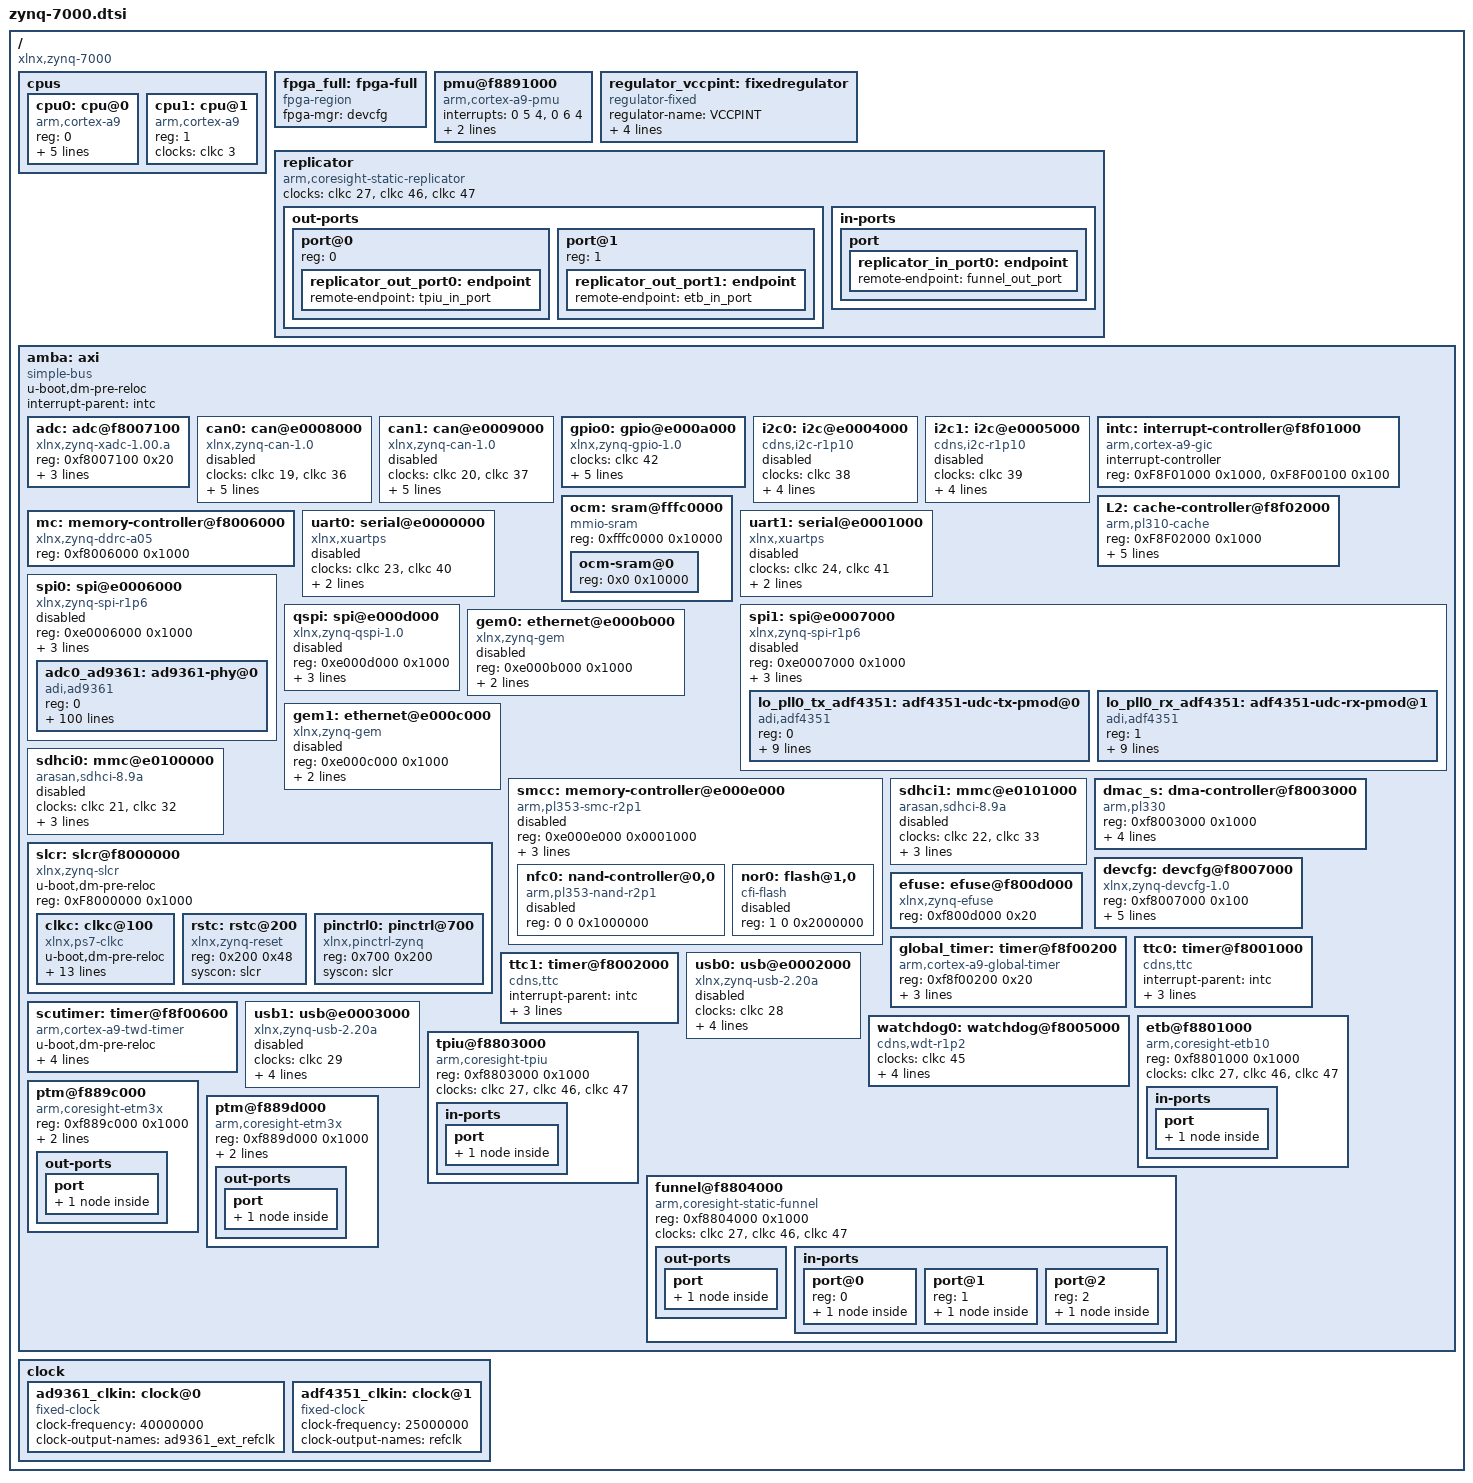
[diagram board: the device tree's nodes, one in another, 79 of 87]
// SPDX-License-Identifier: GPL-2.0+
/*
 * Xilinx Zynq 7000 DTSI
 * Describes the hardware common to all Zynq 7000-based boards.
 *
 *  Copyright (C) 2011 - 2015 Xilinx
 */

/ {
	#address-cells = <1>;
	#size-cells = <1>;
	compatible = "xlnx,zynq-7000";

	cpus {
		#address-cells = <1>;
		#size-cells = <0>;

		cpu0: cpu@0 {
			compatible = "arm,cortex-a9";
			device_type = "cpu";
			reg = <0>;
			clocks = <&clkc 3>;
			clock-latency = <1000>;
			cpu0-supply = <&regulator_vccpint>;
			operating-points = <
				/* kHz    uV */
				666667  1000000
				333334  1000000
			>;
		};

		cpu1: cpu@1 {
			compatible = "arm,cortex-a9";
			device_type = "cpu";
			reg = <1>;
			clocks = <&clkc 3>;
		};
	};

	fpga_full: fpga-full {
		compatible = "fpga-region";
		fpga-mgr = <&devcfg>;
		#address-cells = <1>;
		#size-cells = <1>;
		ranges;
	};

	pmu@f8891000 {
		compatible = "arm,cortex-a9-pmu";
		interrupts = <0 5 4>, <0 6 4>;
		interrupt-parent = <&intc>;
		reg = <0xf8891000 0x1000>,
		      <0xf8893000 0x1000>;
	};

	regulator_vccpint: fixedregulator {
		compatible = "regulator-fixed";
		regulator-name = "VCCPINT";
		regulator-min-microvolt = <1000000>;
		regulator-max-microvolt = <1000000>;
		regulator-boot-on;
		regulator-always-on;
	};

	replicator {
		compatible = "arm,coresight-static-replicator";
		clocks = <&clkc 27>, <&clkc 46>, <&clkc 47>;
		clock-names = "apb_pclk", "dbg_trc", "dbg_apb";

		out-ports {
			#address-cells = <1>;
			#size-cells = <0>;

			/* replicator output ports */
			port@0 {
				reg = <0>;
				replicator_out_port0: endpoint {
					remote-endpoint = <&tpiu_in_port>;
				};
			};
			port@1 {
				reg = <1>;
				replicator_out_port1: endpoint {
					remote-endpoint = <&etb_in_port>;
				};
			};
		};
		in-ports {
			/* replicator input port */
			port {
				replicator_in_port0: endpoint {
					remote-endpoint = <&funnel_out_port>;
				};
			};
		};
	};

	amba: axi {
		u-boot,dm-pre-reloc;
		compatible = "simple-bus";
		#address-cells = <1>;
		#size-cells = <1>;
		interrupt-parent = <&intc>;
		ranges;

		adc: adc@f8007100 {
			compatible = "xlnx,zynq-xadc-1.00.a";
			reg = <0xf8007100 0x20>;
			interrupts = <0 7 4>;
			interrupt-parent = <&intc>;
			clocks = <&clkc 12>;
		};

		can0: can@e0008000 {
			compatible = "xlnx,zynq-can-1.0";
			status = "disabled";
			clocks = <&clkc 19>, <&clkc 36>;
			clock-names = "can_clk", "pclk";
			reg = <0xe0008000 0x1000>;
			interrupts = <0 28 4>;
			interrupt-parent = <&intc>;
			tx-fifo-depth = <0x40>;
			rx-fifo-depth = <0x40>;
		};

		can1: can@e0009000 {
			compatible = "xlnx,zynq-can-1.0";
			status = "disabled";
			clocks = <&clkc 20>, <&clkc 37>;
			clock-names = "can_clk", "pclk";
			reg = <0xe0009000 0x1000>;
			interrupts = <0 51 4>;
			interrupt-parent = <&intc>;
			tx-fifo-depth = <0x40>;
			rx-fifo-depth = <0x40>;
		};

		gpio0: gpio@e000a000 {
			compatible = "xlnx,zynq-gpio-1.0";
			#gpio-cells = <2>;
			#address-cells = <0>;
			clocks = <&clkc 42>;
			gpio-controller;
			interrupt-controller;
			#interrupt-cells = <2>;
			interrupt-parent = <&intc>;
			interrupts = <0 20 4>;
			reg = <0xe000a000 0x1000>;
		};

		i2c0: i2c@e0004000 {
			compatible = "cdns,i2c-r1p10";
			status = "disabled";
			clocks = <&clkc 38>;
			interrupt-parent = <&intc>;
			interrupts = <0 25 4>;
			clock-frequency = <400000>;
			reg = <0xe0004000 0x1000>;
			#address-cells = <1>;
			#size-cells = <0>;
		};

		i2c1: i2c@e0005000 {
			compatible = "cdns,i2c-r1p10";
			status = "disabled";
			clocks = <&clkc 39>;
			interrupt-parent = <&intc>;
			interrupts = <0 48 4>;
			clock-frequency = <400000>;
			reg = <0xe0005000 0x1000>;
			#address-cells = <1>;
			#size-cells = <0>;
		};

		intc: interrupt-controller@f8f01000 {
			compatible = "arm,cortex-a9-gic";
			#interrupt-cells = <3>;
			#address-cells = <0>;
			interrupt-controller;
			reg = <0xF8F01000 0x1000>,
			      <0xF8F00100 0x100>;
		};

		L2: cache-controller@f8f02000 {
			compatible = "arm,pl310-cache";
			reg = <0xF8F02000 0x1000>;
			interrupts = <0 2 4>;
			arm,data-latency = <3 2 2>;
			arm,tag-latency = <2 2 2>;
			cache-unified;
			cache-level = <2>;
		};

		mc: memory-controller@f8006000 {
			compatible = "xlnx,zynq-ddrc-a05";
			reg = <0xf8006000 0x1000>;
		};

		ocm: sram@fffc0000 {
			compatible = "mmio-sram";
			reg = <0xfffc0000 0x10000>;
			#address-cells = <1>;
			#size-cells = <1>;
			ranges = <0 0xfffc0000 0x10000>;
			ocm-sram@0 {
				reg = <0x0 0x10000>;
			};
		};

		uart0: serial@e0000000 {
			compatible = "xlnx,xuartps", "cdns,uart-r1p8";
			status = "disabled";
			clocks = <&clkc 23>, <&clkc 40>;
			clock-names = "uart_clk", "pclk";
			reg = <0xE0000000 0x1000>;
			interrupts = <0 27 4>;
		};

		uart1: serial@e0001000 {
			compatible = "xlnx,xuartps", "cdns,uart-r1p8";
			status = "disabled";
			clocks = <&clkc 24>, <&clkc 41>;
			clock-names = "uart_clk", "pclk";
			reg = <0xE0001000 0x1000>;
			interrupts = <0 50 4>;
		};

		spi0: spi@e0006000 {
			compatible = "xlnx,zynq-spi-r1p6";
			reg = <0xe0006000 0x1000>;
			status = "disabled";
			interrupt-parent = <&intc>;
			interrupts = <0 26 4>;
			clocks = <&clkc 25>, <&clkc 34>;
			clock-names = "ref_clk", "pclk";
			#address-cells = <1>;
			#size-cells = <0>;
			adc0_ad9361: ad9361-phy@0 {
				compatible = "adi,ad9361";
				reg = <0>;

				/* SPI Setup */
				spi-cpha;
				spi-max-frequency = <10000000>;

				/* Clocks */
				clocks = <&ad9361_clkin 0>;
				clock-names = "ad9361_ext_refclk";
				clock-output-names = "rx_sampl_clk", "tx_sampl_clk";
				#clock-cells = <1>;

				//adi,debug-mode-enable;
				/* Digital Interface Control */

				/* adi,digital-interface-tune-skip-mode:
				* 0 = TUNE RX&TX
				* 1 = SKIP TX
				* 2 = SKIP ALL
				*/
				adi,digital-interface-tune-skip-mode = <0>;

				adi,pp-tx-swap-enable;
				adi,pp-rx-swap-enable;
				adi,rx-frame-pulse-mode-enable;
				adi,lvds-mode-enable;
				adi,lvds-bias-mV = <150>;
				adi,lvds-rx-onchip-termination-enable;
				adi,rx-data-delay = <4>;
				adi,tx-fb-clock-delay = <7>;

				//adi,fdd-rx-rate-2tx-enable;

				adi,dcxo-coarse-and-fine-tune = <8 5920>;
				//adi,xo-disable-use-ext-refclk-enable;

				/* Mode Setup */

				adi,2rx-2tx-mode-enable;
				//adi,split-gain-table-mode-enable;

				/* ENSM Mode */
				adi,frequency-division-duplex-mode-enable;
				//adi,ensm-enable-pin-pulse-mode-enable;
				//adi,ensm-enable-txnrx-control-enable;


				/* adi,rx-rf-port-input-select:
				* 0 = (RX1A_N &  RX1A_P) and (RX2A_N & RX2A_P) enabled; balanced
				* 1 = (RX1B_N &  RX1B_P) and (RX2B_N & RX2B_P) enabled; balanced
				* 2 = (RX1C_N &  RX1C_P) and (RX2C_N & RX2C_P) enabled; balanced
				*
				* 3 = RX1A_N and RX2A_N enabled; unbalanced
				* 4 = RX1A_P and RX2A_P enabled; unbalanced
				* 5 = RX1B_N and RX2B_N enabled; unbalanced
				* 6 = RX1B_P and RX2B_P enabled; unbalanced
				* 7 = RX1C_N and RX2C_N enabled; unbalanced
				* 8 = RX1C_P and RX2C_P enabled; unbalanced
				*/

				adi,rx-rf-port-input-select = <0>; /* (RX1A_N &  RX1A_P) and (RX2A_N & RX2A_P) enabled; balanced */

				/* adi,tx-rf-port-input-select:
				* 0	TX1A, TX2A
				* 1	TX1B, TX2B
				*/

				adi,tx-rf-port-input-select = <0>; /* TX1A, TX2A */
				//adi,update-tx-gain-in-alert-enable;
				adi,tx-attenuation-mdB = <10000>;
				adi,tx-lo-powerdown-managed-enable;

				adi,rf-rx-bandwidth-hz = <18000000>;
				adi,rf-tx-bandwidth-hz = <18000000>;
				adi,rx-synthesizer-frequency-hz = /bits/ 64 <2400000000>;
				adi,tx-synthesizer-frequency-hz = /bits/ 64 <2450000000>;

				/*				BBPLL     ADC        R2CLK     R1CLK    CLKRF    RSAMPL  */
				adi,rx-path-clock-frequencies = <983040000 245760000 122880000 61440000 30720000 30720000>;
				/*				BBPLL     DAC        T2CLK     T1CLK    CLKTF    TSAMPL  */
				adi,tx-path-clock-frequencies = <983040000 122880000 122880000 61440000 30720000 30720000>;

				/* Gain Control */

				//adi,gaintable-name = "ad9361_std_gaintable";

				/* adi,gc-rx[1|2]-mode:
				* 0 = RF_GAIN_MGC
				* 1 = RF_GAIN_FASTATTACK_AGC
				* 2 = RF_GAIN_SLOWATTACK_AGC
				* 3 = RF_GAIN_HYBRID_AGC
				*/

				adi,gc-rx1-mode = <2>;
				adi,gc-rx2-mode = <2>;
				adi,gc-adc-ovr-sample-size = <4>; /* sum 4 samples */
				adi,gc-adc-small-overload-thresh = <47>; /* sum of squares */
				adi,gc-adc-large-overload-thresh = <58>; /* sum of squares */
				adi,gc-lmt-overload-high-thresh = <800>; /* mV */
				adi,gc-lmt-overload-low-thresh = <704>; /* mV */
				adi,gc-dec-pow-measurement-duration = <8192>; /* 0..524288 Samples */
				adi,gc-low-power-thresh = <24>; /* 0..-64 dBFS vals are set pos */
				//adi,gc-dig-gain-enable;
				//adi,gc-max-dig-gain = <15>;

				/* Manual Gain Control Setup */

				//adi,mgc-rx1-ctrl-inp-enable; /* uncomment to use ctrl inputs */
				//adi,mgc-rx2-ctrl-inp-enable; /* uncomment to use ctrl inputs */
				adi,mgc-inc-gain-step = <2>;
				adi,mgc-dec-gain-step = <2>;

				/* adi,mgc-split-table-ctrl-inp-gain-mode:
				* (relevant if adi,split-gain-table-mode-enable is set)
				* 0 = AGC determine this
				* 1 = only in LPF
				* 2 = only in LMT
				*/

				adi,mgc-split-table-ctrl-inp-gain-mode = <0>;

				/* Automatic Gain Control Setup */

				adi,agc-attack-delay-extra-margin-us= <1>; /* us */
				adi,agc-outer-thresh-high = <5>; /* -dBFS */
				adi,agc-outer-thresh-high-dec-steps = <2>; /* 0..15 */
				adi,agc-inner-thresh-high = <10>; /* -dBFS */
				adi,agc-inner-thresh-high-dec-steps = <1>; /* 0..7 */
				adi,agc-inner-thresh-low = <12>; /* -dBFS */
				adi,agc-inner-thresh-low-inc-steps = <1>; /* 0..7 */
				adi,agc-outer-thresh-low = <18>; /* -dBFS */
				adi,agc-outer-thresh-low-inc-steps = <2>; /* 0..15 */

				adi,agc-adc-small-overload-exceed-counter = <10>; /* 0..15 */
				adi,agc-adc-large-overload-exceed-counter = <10>; /* 0..15 */
				adi,agc-adc-large-overload-inc-steps = <2>; /* 0..15 */
				//adi,agc-adc-lmt-small-overload-prevent-gain-inc-enable;
				adi,agc-lmt-overload-large-exceed-counter = <10>; /* 0..15 */
				adi,agc-lmt-overload-small-exceed-counter = <10>; /* 0..15 */
				adi,agc-lmt-overload-large-inc-steps = <2>; /* 0..7 */
				//adi,agc-dig-saturation-exceed-counter = <3>; /* 0..15 */
				//adi,agc-dig-gain-step-size = <4>; /* 1..8 */

				//adi,agc-sync-for-gain-counter-enable;
				adi,agc-gain-update-interval-us = <1000>;  /* 1ms */
				//adi,agc-immed-gain-change-if-large-adc-overload-enable;
				//adi,agc-immed-gain-change-if-large-lmt-overload-enable;

				/* Fast AGC */

				adi,fagc-dec-pow-measurement-duration = <64>; /* 64 Samples */
                //adi,fagc-allow-agc-gain-increase-enable;
                adi,fagc-lp-thresh-increment-steps = <1>;
                adi,fagc-lp-thresh-increment-time = <5>;

                adi,fagc-energy-lost-stronger-sig-gain-lock-exit-cnt = <8>;
                adi,fagc-final-overrange-count = <3>;
                //adi,fagc-gain-increase-after-gain-lock-enable;
                adi,fagc-gain-index-type-after-exit-rx-mode = <0>;
                adi,fagc-lmt-final-settling-steps = <1>;
                adi,fagc-lock-level = <10>;
                adi,fagc-lock-level-gain-increase-upper-limit = <5>;
                adi,fagc-lock-level-lmt-gain-increase-enable;

                adi,fagc-lpf-final-settling-steps = <1>;
                adi,fagc-optimized-gain-offset = <5>;
                adi,fagc-power-measurement-duration-in-state5 = <64>;
                adi,fagc-rst-gla-engergy-lost-goto-optim-gain-enable;
                adi,fagc-rst-gla-engergy-lost-sig-thresh-below-ll = <10>;
                adi,fagc-rst-gla-engergy-lost-sig-thresh-exceeded-enable;
                adi,fagc-rst-gla-if-en-agc-pulled-high-mode = <0>;
                adi,fagc-rst-gla-large-adc-overload-enable;
                adi,fagc-rst-gla-large-lmt-overload-enable;
                adi,fagc-rst-gla-stronger-sig-thresh-above-ll = <10>;
                adi,fagc-rst-gla-stronger-sig-thresh-exceeded-enable;
                adi,fagc-state-wait-time-ns = <260>;
                adi,fagc-use-last-lock-level-for-set-gain-enable;

				/* RSSI */

				/* adi,rssi-restart-mode:
				* 0 = AGC_IN_FAST_ATTACK_MODE_LOCKS_THE_GAIN,
				* 1 = EN_AGC_PIN_IS_PULLED_HIGH,
				* 2 = ENTERS_RX_MODE,
				* 3 = GAIN_CHANGE_OCCURS,
				* 4 = SPI_WRITE_TO_REGISTER,
				* 5 = GAIN_CHANGE_OCCURS_OR_EN_AGC_PIN_PULLED_HIGH,
				*/
				adi,rssi-restart-mode = <3>;
				//adi,rssi-unit-is-rx-samples-enable;
				adi,rssi-delay = <1>; /* 1us */
				adi,rssi-wait = <1>; /* 1us */
				adi,rssi-duration = <1000>; /* 1ms */

				/* Control Outputs */
				adi,ctrl-outs-index = <0>;
				adi,ctrl-outs-enable-mask = <0xFF>;

				/* AuxADC Temp Sense Control */

				adi,temp-sense-measurement-interval-ms = <1000>;
				adi,temp-sense-offset-signed = <0xCE>;
				adi,temp-sense-periodic-measurement-enable;

				/* AuxDAC Control */

				adi,aux-dac-manual-mode-enable;

				adi,aux-dac1-default-value-mV = <0>;
				//adi,aux-dac1-active-in-rx-enable;
				//adi,aux-dac1-active-in-tx-enable;
				//adi,aux-dac1-active-in-alert-enable;
				adi,aux-dac1-rx-delay-us = <0>;
				adi,aux-dac1-tx-delay-us = <0>;

				adi,aux-dac2-default-value-mV = <0>;
				//adi,aux-dac2-active-in-rx-enable;
				//adi,aux-dac2-active-in-tx-enable;
				//adi,aux-dac2-active-in-alert-enable;
				adi,aux-dac2-rx-delay-us = <0>;
				adi,aux-dac2-tx-delay-us = <0>;
			};
			
		};

		spi1: spi@e0007000 {
			compatible = "xlnx,zynq-spi-r1p6";
			reg = <0xe0007000 0x1000>;
			status = "disabled";
			interrupt-parent = <&intc>;
			interrupts = <0 49 4>;
			clocks = <&clkc 26>, <&clkc 35>;
			clock-names = "ref_clk", "pclk";
			#address-cells = <1>;
			#size-cells = <0>;

			lo_pll0_tx_adf4351: adf4351-udc-tx-pmod@0 {
				compatible = "adi,adf4351";
				reg = <0>;

				spi-max-frequency = <10000000>;

				clocks = <&adf4351_clkin>;
				clock-names = "clkin";

				adi,channel-spacing = <1000000>;
				adi,power-up-frequency = <370000000>;
				adi,phase-detector-polarity-positive-enable;
				adi,charge-pump-current = <2500>;
				adi,output-power = <3>;
				adi,mute-till-lock-enable;
				adi,muxout-select = <6>;
			};

			lo_pll0_rx_adf4351: adf4351-udc-rx-pmod@1 {
				compatible = "adi,adf4351";
				reg = <1>;

				spi-max-frequency = <10000000>;

				clocks = <&adf4351_clkin>;
				clock-names = "clkin";

				adi,channel-spacing = <1000000>;
				adi,power-up-frequency = <340000000>;
				adi,phase-detector-polarity-positive-enable;
				adi,charge-pump-current = <2500>;
				adi,output-power = <3>;
				adi,mute-till-lock-enable;
				adi,muxout-select = <6>;
			};
		};

		qspi: spi@e000d000 {
			compatible = "xlnx,zynq-qspi-1.0";
			reg = <0xe000d000 0x1000>;
			interrupt-parent = <&intc>;
			interrupts = <0 19 4>;
			clocks = <&clkc 10>, <&clkc 43>;
			clock-names = "ref_clk", "pclk";
			status = "disabled";
			#address-cells = <1>;
			#size-cells = <0>;
		};

		gem0: ethernet@e000b000 {
			compatible = "xlnx,zynq-gem", "cdns,gem";
			reg = <0xe000b000 0x1000>;
			status = "disabled";
			interrupts = <0 22 4>;
			clocks = <&clkc 30>, <&clkc 30>, <&clkc 13>;
			clock-names = "pclk", "hclk", "tx_clk";
			#address-cells = <1>;
			#size-cells = <0>;
		};

		gem1: ethernet@e000c000 {
			compatible = "xlnx,zynq-gem", "cdns,gem";
			reg = <0xe000c000 0x1000>;
			status = "disabled";
			interrupts = <0 45 4>;
			clocks = <&clkc 31>, <&clkc 31>, <&clkc 14>;
			clock-names = "pclk", "hclk", "tx_clk";
			#address-cells = <1>;
			#size-cells = <0>;
		};

		smcc: memory-controller@e000e000 {
			compatible = "arm,pl353-smc-r2p1", "arm,primecell";
			reg = <0xe000e000 0x0001000>;
			status = "disabled";
			clock-names = "memclk", "apb_pclk";
			clocks = <&clkc 11>, <&clkc 44>;
			ranges = <0x0 0x0 0xe1000000 0x1000000 /* Nand CS region */
				  0x1 0x0 0xe2000000 0x2000000 /* SRAM/NOR CS0 region */
				  0x2 0x0 0xe4000000 0x2000000>; /* SRAM/NOR CS1 region */
			#address-cells = <2>;
			#size-cells = <1>;
			interrupt-parent = <&intc>;
			interrupts = <0 18 4>;

			nfc0: nand-controller@0,0 {
				compatible = "arm,pl353-nand-r2p1";
				reg = <0 0 0x1000000>;
				status = "disabled";
				#address-cells = <1>;
				#size-cells = <0>;
			};
			nor0: flash@1,0 {
				status = "disabled";
				compatible = "cfi-flash";
				reg = <1 0 0x2000000>;
				#address-cells = <1>;
				#size-cells = <1>;
			};
		};

		sdhci0: mmc@e0100000 {
			compatible = "arasan,sdhci-8.9a";
			status = "disabled";
			clock-names = "clk_xin", "clk_ahb";
			clocks = <&clkc 21>, <&clkc 32>;
			interrupt-parent = <&intc>;
			interrupts = <0 24 4>;
			reg = <0xe0100000 0x1000>;
		};

		sdhci1: mmc@e0101000 {
			compatible = "arasan,sdhci-8.9a";
			status = "disabled";
			clock-names = "clk_xin", "clk_ahb";
			clocks = <&clkc 22>, <&clkc 33>;
			interrupt-parent = <&intc>;
			interrupts = <0 47 4>;
			reg = <0xe0101000 0x1000>;
		};

		slcr: slcr@f8000000 {
			u-boot,dm-pre-reloc;
			#address-cells = <1>;
			#size-cells = <1>;
			compatible = "xlnx,zynq-slcr", "syscon", "simple-mfd";
			reg = <0xF8000000 0x1000>;
			ranges;
			clkc: clkc@100 {
				u-boot,dm-pre-reloc;
				#clock-cells = <1>;
				compatible = "xlnx,ps7-clkc";
				fclk-enable = <0xf>;
				clock-output-names = "armpll", "ddrpll", "iopll", "cpu_6or4x",
						"cpu_3or2x", "cpu_2x", "cpu_1x", "ddr2x", "ddr3x",
						"dci", "lqspi", "smc", "pcap", "gem0", "gem1",
						"fclk0", "fclk1", "fclk2", "fclk3", "can0", "can1",
						"sdio0", "sdio1", "uart0", "uart1", "spi0", "spi1",
						"dma", "usb0_aper", "usb1_aper", "gem0_aper",
						"gem1_aper", "sdio0_aper", "sdio1_aper",
						"spi0_aper", "spi1_aper", "can0_aper", "can1_aper",
						"i2c0_aper", "i2c1_aper", "uart0_aper", "uart1_aper",
						"gpio_aper", "lqspi_aper", "smc_aper", "swdt",
						"dbg_trc", "dbg_apb";
				reg = <0x100 0x100>;
			};

			rstc: rstc@200 {
				compatible = "xlnx,zynq-reset";
				reg = <0x200 0x48>;
				#reset-cells = <1>;
				syscon = <&slcr>;
			};

			pinctrl0: pinctrl@700 {
				compatible = "xlnx,pinctrl-zynq";
				reg = <0x700 0x200>;
				syscon = <&slcr>;
			};
		};

		dmac_s: dma-controller@f8003000 {
			compatible = "arm,pl330", "arm,primecell";
			reg = <0xf8003000 0x1000>;
			interrupt-parent = <&intc>;
			/*
			 * interrupt-names = "abort", "dma0", "dma1", "dma2", "dma3",
			 * "dma4", "dma5", "dma6", "dma7";
			 */
			interrupts = <0 13 4>,
			             <0 14 4>, <0 15 4>,
			             <0 16 4>, <0 17 4>,
			             <0 40 4>, <0 41 4>,
			             <0 42 4>, <0 43 4>;
			#dma-cells = <1>;
			clocks = <&clkc 27>;
			clock-names = "apb_pclk";
		};

		devcfg: devcfg@f8007000 {
			compatible = "xlnx,zynq-devcfg-1.0";
			reg = <0xf8007000 0x100>;
			interrupt-parent = <&intc>;
			interrupts = <0 8 4>;
			clocks = <&clkc 12>, <&clkc 15>, <&clkc 16>, <&clkc 17>, <&clkc 18>;
			clock-names = "ref_clk", "fclk0", "fclk1", "fclk2", "fclk3";
			syscon = <&slcr>;
		};

		efuse: efuse@f800d000 {
			compatible = "xlnx,zynq-efuse";
			reg = <0xf800d000 0x20>;
		};

		global_timer: timer@f8f00200 {
			compatible = "arm,cortex-a9-global-timer";
			reg = <0xf8f00200 0x20>;
			interrupts = <1 11 0x301>;
			interrupt-parent = <&intc>;
			clocks = <&clkc 4>;
		};

		ttc0: timer@f8001000 {
			interrupt-parent = <&intc>;
			interrupts = <0 10 4>, <0 11 4>, <0 12 4>;
			compatible = "cdns,ttc";
			clocks = <&clkc 6>;
			reg = <0xF8001000 0x1000>;
		};

		ttc1: timer@f8002000 {
			interrupt-parent = <&intc>;
			interrupts = <0 37 4>, <0 38 4>, <0 39 4>;
			compatible = "cdns,ttc";
			clocks = <&clkc 6>;
			reg = <0xF8002000 0x1000>;
		};

		scutimer: timer@f8f00600 {
			u-boot,dm-pre-reloc;
			interrupt-parent = <&intc>;
			interrupts = <1 13 0x301>;
			compatible = "arm,cortex-a9-twd-timer";
			reg = <0xf8f00600 0x20>;
			clocks = <&clkc 4>;
		};

		usb0: usb@e0002000 {
			compatible = "xlnx,zynq-usb-2.20a", "chipidea,usb2";
			status = "disabled";
			clocks = <&clkc 28>;
			interrupt-parent = <&intc>;
			interrupts = <0 21 4>;
			reg = <0xe0002000 0x1000>;
			phy_type = "ulpi";
		};

		usb1: usb@e0003000 {
			compatible = "xlnx,zynq-usb-2.20a", "chipidea,usb2";
			status = "disabled";
			clocks = <&clkc 29>;
			interrupt-parent = <&intc>;
			interrupts = <0 44 4>;
			reg = <0xe0003000 0x1000>;
			phy_type = "ulpi";
		};

		watchdog0: watchdog@f8005000 {
			clocks = <&clkc 45>;
			compatible = "cdns,wdt-r1p2";
			interrupt-parent = <&intc>;
			interrupts = <0 9 1>;
			reg = <0xf8005000 0x1000>;
			timeout-sec = <10>;
		};

		etb@f8801000 {
			compatible = "arm,coresight-etb10", "arm,primecell";
			reg = <0xf8801000 0x1000>;
			clocks = <&clkc 27>, <&clkc 46>, <&clkc 47>;
			clock-names = "apb_pclk", "dbg_trc", "dbg_apb";
			in-ports {
				port {
					etb_in_port: endpoint {
						remote-endpoint = <&replicator_out_port1>;
					};
				};
			};
		};

		tpiu@f8803000 {
			compatible = "arm,coresight-tpiu", "arm,primecell";
			reg = <0xf8803000 0x1000>;
			clocks = <&clkc 27>, <&clkc 46>, <&clkc 47>;
			clock-names = "apb_pclk", "dbg_trc", "dbg_apb";
			in-ports {
				port {
					tpiu_in_port: endpoint {
						remote-endpoint = <&replicator_out_port0>;
					};
				};
			};
		};

		funnel@f8804000 {
			compatible = "arm,coresight-static-funnel", "arm,primecell";
			reg = <0xf8804000 0x1000>;
			clocks = <&clkc 27>, <&clkc 46>, <&clkc 47>;
			clock-names = "apb_pclk", "dbg_trc", "dbg_apb";

			/* funnel output ports */
			out-ports {
				port {
					funnel_out_port: endpoint {
						remote-endpoint =
							<&replicator_in_port0>;
					};
				};
			};

			in-ports {
				#address-cells = <1>;
				#size-cells = <0>;

				/* funnel input ports */
				port@0 {
					reg = <0>;
					funnel0_in_port0: endpoint {
						remote-endpoint = <&ptm0_out_port>;
					};
				};

				port@1 {
					reg = <1>;
					funnel0_in_port1: endpoint {
						remote-endpoint = <&ptm1_out_port>;
					};
				};

				port@2 {
					reg = <2>;
					funnel0_in_port2: endpoint {
					};
				};
				/* The other input ports are not connect to anything */
			};
		};

		ptm@f889c000 {
			compatible = "arm,coresight-etm3x", "arm,primecell";
			reg = <0xf889c000 0x1000>;
			clocks = <&clkc 27>, <&clkc 46>, <&clkc 47>;
			clock-names = "apb_pclk", "dbg_trc", "dbg_apb";
			cpu = <&cpu0>;
			out-ports {
				port {
					ptm0_out_port: endpoint {
						remote-endpoint = <&funnel0_in_port0>;
					};
				};
			};
		};

		ptm@f889d000 {
			compatible = "arm,coresight-etm3x", "arm,primecell";
			reg = <0xf889d000 0x1000>;
			clocks = <&clkc 27>, <&clkc 46>, <&clkc 47>;
			clock-names = "apb_pclk", "dbg_trc", "dbg_apb";
			cpu = <&cpu1>;
			out-ports {
				port {
					ptm1_out_port: endpoint {
						remote-endpoint = <&funnel0_in_port1>;
					};
				};
			};
		};
	};

	clock{
		ad9361_clkin:clock@0 {
			compatible = "fixed-clock";

			clock-frequency = <40000000>;
			clock-output-names = "ad9361_ext_refclk";
			#clock-cells = <0>;
		};
		adf4351_clkin: clock@1 {
			compatible = "fixed-clock";

			clock-frequency = <25000000>;
			clock-output-names = "refclk";
			#clock-cells = <0>;
		};
	};

	
};

